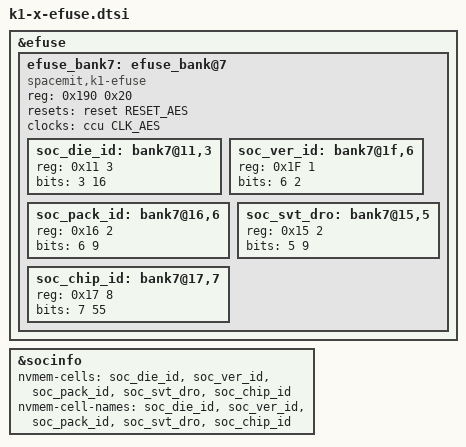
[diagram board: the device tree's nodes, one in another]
// SPDX-License-Identifier: (GPL-2.0 OR MIT)
/* Copyright (c) 2024 Spacemit, Inc */

&efuse {
	status = "okay";

	efuse_bank7: efuse_bank@7 {
		compatible = "spacemit,k1-efuse";
		#address-cells = <1>;
		#size-cells = <1>;
		reg = <0x190 0x20>;
		resets = <&reset RESET_AES>;
		reset-names = "aes_reset";
		clocks = <&ccu CLK_AES>;
		clock-names = "aes_core";
		status = "okay";

		soc_die_id: bank7@11,3 {
			reg = <0x11 3>;
			bits = <3 16>;
		};

		soc_ver_id: bank7@1f,6 {
			reg = <0x1F 1>;
			bits = <6 2>;
		};

		soc_pack_id: bank7@16,6 {
			reg = <0x16 2>;
			bits = <6 9>;
		};

		soc_svt_dro: bank7@15,5 {
			reg = <0x15 2>;
			bits = <5 9>;
		};

		soc_chip_id: bank7@17,7 {
			reg = <0x17 8>;
			bits = <7 55>;
		};
	};
};

&socinfo {
	nvmem-cells = <&soc_die_id>, <&soc_ver_id>, <&soc_pack_id>,
			<&soc_svt_dro>, <&soc_chip_id>;
	nvmem-cell-names = "soc_die_id", "soc_ver_id", "soc_pack_id",
			"soc_svt_dro", "soc_chip_id";
	status = "okay";
};

